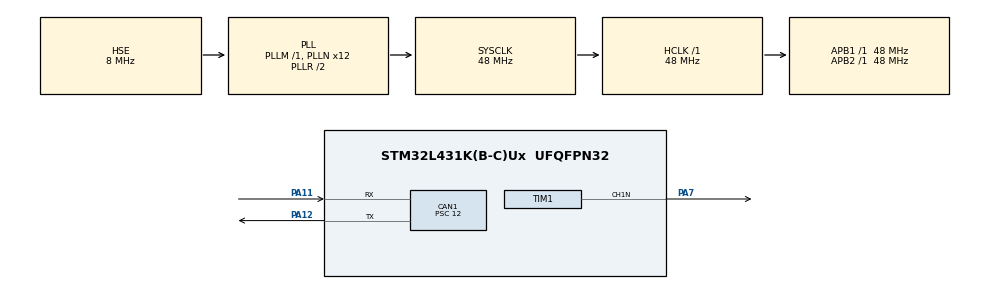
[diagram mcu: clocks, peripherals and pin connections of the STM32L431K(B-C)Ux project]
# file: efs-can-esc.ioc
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CAN1.BS1=CAN_BS1_2TQ
CAN1.CalculateBaudRate=1000000
CAN1.CalculateTimeBit=1000
CAN1.CalculateTimeQuantum=250.0
CAN1.Prescaler=12
Dma.Request0=TIM1_CH1
Dma.TIM1_CH1.0.Direction=DMA_MEMORY_TO_PERIPH
Dma.TIM1_CH1.0.Instance=DMA1_Channel2
Dma.TIM1_CH1.0.MemDataAlignment=DMA_MDATAALIGN_WORD
Dma.TIM1_CH1.0.MemInc=DMA_MINC_ENABLE
Dma.TIM1_CH1.0.Mode=DMA_CIRCULAR
Dma.TIM1_CH1.0.PeriphDataAlignment=DMA_PDATAALIGN_WORD
Dma.TIM1_CH1.0.PeriphInc=DMA_PINC_DISABLE
Dma.TIM1_CH1.0.Priority=DMA_PRIORITY_LOW
Mcu.Family=STM32L4
Mcu.Name=STM32L431K(B-C)Ux
Mcu.Package=UFQFPN32
NVIC.CAN1_RX0_IRQn=true\:0\:0\:false\:false\:true\:true\:true\:true
NVIC.DMA1_Channel2_IRQn=true\:0\:0\:false\:false\:true\:false\:true\:true
NVIC.PriorityGroup=NVIC_PRIORITYGROUP_4
PA0.Mode=HSE-External-Clock-Source-for-LittleOrca
PA0.Signal=RCC_CK_IN
PA11.GPIO_PuPd=GPIO_PULLUP
PA11.Mode=CAN_Activate
PA11.Signal=CAN1_RX
PA12.Mode=CAN_Activate
PA12.Signal=CAN1_TX
PA13\ (JTMS-SWDIO).Mode=Trace_Asynchronous_SW
PA13\ (JTMS-SWDIO).Signal=SYS_JTMS-SWDIO
PA14\ (JTCK-SWCLK).Mode=Trace_Asynchronous_SW
PA14\ (JTCK-SWCLK).Signal=SYS_JTCK-SWCLK
PA7.Mode=PWM Generation1 CH1N
PA7.Signal=TIM1_CH1N
PB3\ (JTDO-TRACESWO).Mode=Trace_Asynchronous_SW
PB3\ (JTDO-TRACESWO).Signal=SYS_JTDO-SWO
ProjectManager.HeapSize=0x200
ProjectManager.StackSize=0x400
ProjectManager.TargetToolchain=STM32CubeIDE
RCC.ADCFreq_Value=32000000
RCC.AHBFreq_Value=48000000
RCC.APB1Freq_Value=48000000
RCC.APB1TimFreq_Value=48000000
RCC.APB2Freq_Value=48000000
RCC.APB2TimFreq_Value=48000000
RCC.CortexFreq_Value=48000000
RCC.HCLKFreq_Value=48000000
RCC.HSE_VALUE=8000000
RCC.HSI48_VALUE=48000000
RCC.HSI_VALUE=16000000
RCC.LSE_VALUE=32768
RCC.MSI_VALUE=4000000
RCC.PLLN=12
RCC.PLLSourceVirtual=RCC_PLLSOURCE_HSE
RCC.SYSCLKFreq_VALUE=48000000
RCC.SYSCLKSource=RCC_SYSCLKSOURCE_PLLCLK
RCC.VCOOutputFreq_Value=96000000
TIM1.Channel-PWM\ Generation1\ CH1N=TIM_CHANNEL_1
TIM1.OCMode_PWM-PWM\ Generation1\ CH1N=TIM_OCMODE_PWM1
TIM1.OCNIdleState_1=TIM_OCNIDLESTATE_SET
TIM1.Period=320
VP_TIM1_VS_ClockSourceINT.Mode=Internal
board=custom

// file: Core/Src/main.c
/* USER CODE BEGIN Header */
/**
  ******************************************************************************
  * @file           : main.c
  * @brief          : Main program body
  ******************************************************************************
  * @attention
  *
  * Copyright (c) 2024 STMicroelectronics.
  * All rights reserved.
  *
  * This software is licensed under terms that can be found in the LICENSE file
  * in the root directory of this software component.
  * If no LICENSE file comes with this software, it is provided AS-IS.
  *
  ******************************************************************************
  */
/* USER CODE END Header */
#include "main.h"

/* USER CODE BEGIN Includes */
#include <canard.h>
#include <canard_stm32_driver.h>
#include <dronecan_msgs.h>
#include <Dshot.h>
#include <node_settings.h>
#include <stdio.h>
#include <string.h>
/* USER CODE END Includes */

CAN_HandleTypeDef hcan1;

TIM_HandleTypeDef htim1;
DMA_HandleTypeDef hdma_tim1_ch1;

/* USER CODE BEGIN PV */
CanardInstance canard;
DShotConfig_t dshotConfig = {};
float global_throttle = 0.0;
uint8_t memory_pool[1024];
static struct uavcan_protocol_NodeStatus node_status;
/* USER CODE END PV */

void SystemClock_Config(void);
static void MX_GPIO_Init(void);
static void MX_DMA_Init(void);
static void MX_TIM1_Init(void);
static void MX_CAN1_Init(void);

/* USER CODE BEGIN 0 */

// NOTE: All canard handlers and senders are based on this reference: https://dronecan.github.io/Specification/7._List_of_standard_data_types/
// Alternatively, you can look at the corresponding generated header file in the dsdlc_generated folder

// Canard Handlers ( Many have code copied from libcanard esc_node example: https://github.com/dronecan/libcanard/blob/master/examples/ESCNode/esc_node.c )

void handle_NodeStatus(CanardInstance *ins, CanardRxTransfer *transfer) {
	struct uavcan_protocol_NodeStatus nodeStatus;

	if (uavcan_protocol_NodeStatus_decode(transfer, &nodeStatus)) {
		return;
	}

	printf("Node health: %ud Node Mode: %ud\n", nodeStatus.health, nodeStatus.mode);

	printf("Node Health ");

	switch (nodeStatus.health) {
	case UAVCAN_PROTOCOL_NODESTATUS_HEALTH_OK:
		printf("OK\n");
		break;
	case UAVCAN_PROTOCOL_NODESTATUS_HEALTH_WARNING:
		printf("WARNING\n");
		break;
	case UAVCAN_PROTOCOL_NODESTATUS_HEALTH_ERROR:
		printf("ERROR\n");
		break;
	case UAVCAN_PROTOCOL_NODESTATUS_HEALTH_CRITICAL:
		printf("CRITICAL\n");
		break;
	default:
		printf("UNKNOWN?\n");
		break;
	}

	printf("Node Mode ");

	switch(nodeStatus.mode) {
	case UAVCAN_PROTOCOL_NODESTATUS_MODE_OPERATIONAL:
		printf("OPERATIONAL\n");
		break;
	case UAVCAN_PROTOCOL_NODESTATUS_MODE_INITIALIZATION:
		printf("INITIALIZATION\n");
		break;
	case UAVCAN_PROTOCOL_NODESTATUS_MODE_MAINTENANCE:
		printf("MAINTENANCE\n");
		break;
	case UAVCAN_PROTOCOL_NODESTATUS_MODE_SOFTWARE_UPDATE:
		printf("SOFTWARE UPDATE\n");
		break;
	case UAVCAN_PROTOCOL_NODESTATUS_MODE_OFFLINE:
		printf("OFFLINE\n");
		break;
	default:
		printf("UNKNOWN?\n");
		break;
	}
}

void handle_NotifyState(CanardInstance *ins, CanardRxTransfer *transfer) {
	struct ardupilot_indication_NotifyState notifyState;

	if (ardupilot_indication_NotifyState_decode(transfer, &notifyState)) {
		return;
	}

	uint32_t nl = notifyState.vehicle_state & 0xFFFFFFFF;  // ignoring the last 32 bits for printing since the highest vehicle_state value right now is 23 even though they're allowed to be up to 64bit unsigned integer

	printf("Vehicle State: %lu ", nl);

	if (notifyState.aux_data.len > 0) {
		printf("Aux Data: 0x");

		for (int i = 0; i < notifyState.aux_data.len; i++) {
			printf("%02x", notifyState.aux_data.data[i]);
		}
	}

	printf("\n");

}

/*
  get a 16 byte unique ID for this node, this should be based on the CPU unique ID or other unique ID
 */
void getUniqueID(uint8_t id[16]) {
    uint32_t HALUniqueIDs[3];
    // Make Unique ID out of the 96-bit STM32 UID and fill the rest with 0s
    memset(id, 0, 16);
    HALUniqueIDs[0] = HAL_GetUIDw0();
    HALUniqueIDs[1] = HAL_GetUIDw1();
    HALUniqueIDs[2] = HAL_GetUIDw2();
    memcpy(id, HALUniqueIDs, 12);
}

/*
  handle a GetNodeInfo request
*/
// TODO: All the data in here is temporary for testing. If actually need to send valid data, edit accordingly.
void handle_GetNodeInfo(CanardInstance *ins, CanardRxTransfer *transfer) {
	printf("GetNodeInfo request from %d\n", transfer->source_node_id);

	uint8_t buffer[UAVCAN_PROTOCOL_GETNODEINFO_RESPONSE_MAX_SIZE];
	struct uavcan_protocol_GetNodeInfoResponse pkt;

	memset(&pkt, 0, sizeof(pkt));

	node_status.uptime_sec = HAL_GetTick() / 1000ULL;
	pkt.status = node_status;

	// fill in your major and minor firmware version
	pkt.software_version.major = 1;
	pkt.software_version.minor = 0;
	pkt.software_version.optional_field_flags = 0;
	pkt.software_version.vcs_commit = 0; // should put git hash in here

	// should fill in hardware version
	pkt.hardware_version.major = 1;
	pkt.hardware_version.minor = 0;

	// just setting all 16 bytes to 1 for testing
	getUniqueID(pkt.hardware_version.unique_id);

	strncpy((char*)pkt.name.data, "ESCNode", sizeof(pkt.name.data));
	pkt.name.len = strnlen((char*)pkt.name.data, sizeof(pkt.name.data));

	uint16_t total_size = uavcan_protocol_GetNodeInfoResponse_encode(&pkt, buffer);

	canardRequestOrRespond(ins,
						   transfer->source_node_id,
						   UAVCAN_PROTOCOL_GETNODEINFO_SIGNATURE,
						   UAVCAN_PROTOCOL_GETNODEINFO_ID,
						   &transfer->transfer_id,
						   transfer->priority,
						   CanardResponse,
						   &buffer[0],
						   total_size);
}

/*
  handle a ESC RawCommand request
*/
void handle_RawCommand(CanardInstance *ins, CanardRxTransfer *transfer)
{
  struct uavcan_equipment_esc_RawCommand rawCommand;
  if (uavcan_equipment_esc_RawCommand_decode(transfer, &rawCommand)) {
    return;
  }

  // see if it is for us
  if (rawCommand.cmd.len <= ESC_INDEX) {
    return;
  }

  // convert throttle to -100 to 100 range and update the global value
  float throttle = rawCommand.cmd.data[ESC_INDEX]/8192.0*100;
  global_throttle = throttle;

}

// CAN ISR
// Run HAL_CAN_ActivateNotification(&hcan1, CAN_IT_RX_FIFO0_MSG_PENDING) once to set up the ISR
void HAL_CAN_RxFifo0MsgPendingCallback(CAN_HandleTypeDef *hcan) {
	// Receiving
	CanardCANFrame rx_frame;

	const uint64_t timestamp = HAL_GetTick() * 1000ULL;
	const int16_t rx_res = canardSTM32Recieve(hcan, CAN_RX_FIFO0, &rx_frame);

	if (rx_res < 0) {
		printf("Receive error %d\n", rx_res);
	}
	else if (rx_res > 0)        // Success - process the frame
	{
		canardHandleRxFrame(&canard, &rx_frame, timestamp);
	}
}

bool shouldAcceptTransfer(const CanardInstance *ins,
                                 uint64_t *out_data_type_signature,
                                 uint16_t data_type_id,
                                 CanardTransferType transfer_type,
                                 uint8_t source_node_id)
{
	if (transfer_type == CanardTransferTypeRequest) {
	// check if we want to handle a specific service request
		switch (data_type_id) {
		case UAVCAN_PROTOCOL_GETNODEINFO_ID: {
			*out_data_type_signature = UAVCAN_PROTOCOL_GETNODEINFO_REQUEST_SIGNATURE;
			return true;
		}
		}
	}
	if (transfer_type == CanardTransferTypeResponse) {
		// check if we want to handle a specific service request
		switch (data_type_id) {
		}
	}
	if (transfer_type == CanardTransferTypeBroadcast) {
		// see if we want to handle a specific broadcast packet
		switch (data_type_id) {
		case UAVCAN_EQUIPMENT_ESC_RAWCOMMAND_ID: {
			*out_data_type_signature = UAVCAN_EQUIPMENT_ESC_RAWCOMMAND_SIGNATURE;
			return true;
		}
		case UAVCAN_PROTOCOL_NODESTATUS_ID: {
			*out_data_type_signature = UAVCAN_PROTOCOL_NODESTATUS_SIGNATURE;
			return true;
		}
		case ARDUPILOT_INDICATION_NOTIFYSTATE_ID: {
			*out_data_type_signature = ARDUPILOT_INDICATION_NOTIFYSTATE_SIGNATURE;
			return true;
		}
		}
	}
	// we don't want any other messages
	return false;
}

void onTransferReceived(CanardInstance *ins, CanardRxTransfer *transfer) {
	// switch on data type ID to pass to the right handler function
//	printf("Transfer type: %du, Transfer ID: %du \n", transfer->transfer_type, transfer->data_type_id);
//	printf("0x");
//		for (int i = 0; i < transfer->payload_len; i++) {
//			printf("%02x", transfer->payload_head[i]);
//		}
//
//		printf("\n");
	if (transfer->transfer_type == CanardTransferTypeRequest) {
		// check if we want to handle a specific service request
		switch (transfer->data_type_id) {
		case UAVCAN_PROTOCOL_GETNODEINFO_ID: {
			handle_GetNodeInfo(ins, transfer);
			break;
		}
		}
	}
	if (transfer->transfer_type == CanardTransferTypeResponse) {
		switch (transfer->data_type_id) {
		}
	}
	if (transfer->transfer_type == CanardTransferTypeBroadcast) {
		// check if we want to handle a specific broadcast message
		switch (transfer->data_type_id) {
		case UAVCAN_EQUIPMENT_ESC_RAWCOMMAND_ID: {
			handle_RawCommand(ins, transfer);
			break;
		}
		case UAVCAN_PROTOCOL_NODESTATUS_ID: {
			handle_NodeStatus(ins, transfer);
			break;
		}
		case ARDUPILOT_INDICATION_NOTIFYSTATE_ID: {
			handle_NotifyState(ins, transfer);
			break;
		}
		}
	}
}

// CAN Filter setup, modify this to your needs
// Run this once before calling HAL_CAN_Start()
void setupCANFilter(CAN_HandleTypeDef *hcan) {
  CAN_FilterTypeDef filter;
  filter.FilterBank = 0;
	filter.FilterMode = CAN_FILTERMODE_IDMASK;
	filter.FilterFIFOAssignment = CAN_RX_FIFO0;
	filter.FilterIdHigh = 0;
	filter.FilterIdLow = 0;
	filter.FilterMaskIdHigh = 0;
	filter.FilterMaskIdLow = 0;
	filter.FilterScale = CAN_FILTERSCALE_32BIT;
	filter.FilterActivation = ENABLE;
	filter.SlaveStartFilterBank = 14;

	HAL_CAN_ConfigFilter(hcan, &filter);
}

/* USER CODE END 0 */

int main(void)
{

  /* MCU Configuration--------------------------------------------------------*/

  /* Reset of all peripherals, Initializes the Flash interface and the Systick. */
  HAL_Init();

  /* Configure the system clock */
  SystemClock_Config();

  /* Initialize all configured peripherals */
  MX_GPIO_Init();
  MX_DMA_Init();
  MX_TIM1_Init();
  MX_CAN1_Init();
  /* USER CODE BEGIN 2 */

  /* Initialize DShot */
  uint32_t buffer[DSHOT_DMA_BUFFER_LEN] = {0};
  dshotConfig.timer = &htim1;
  dshotConfig.timerChannel = TIM_CHANNEL_1;
  dshotConfig.timDMAHandleIndex = TIM_DMA_ID_CC1;
  dshotConfig.dmaBuffer = buffer;
  dshotInit(dshotConfig);

  /* Initialize CAN ISR, CAN Filter, and CAN module  */
  HAL_CAN_ActivateNotification(&hcan1, CAN_IT_RX_FIFO0_MSG_PENDING);
  setupCANFilter(&hcan1);
  HAL_CAN_Start(&hcan1);

  /*
   Initializing the Libcanard instance.
   */
  canardInit(&canard,
			 memory_pool,
			 sizeof(memory_pool),
			 onTransferReceived,
			 shouldAcceptTransfer,
			 NULL);

  // Set a different NODE_ID for each device on the CAN bus by configuring node_settings
  if (NODE_ID > 0) {
	  canardSetLocalNodeID(&canard, NODE_ID);
  } else {
	  printf("Node ID is 0, this node is anonymous and can't transmit most messaged. Please update this in node_settings.h\n");
  }

  /* USER CODE END 2 */

  /* Infinite loop */
  /* USER CODE BEGIN WHILE */
  while (1)
  {
    // global_throttle is updated by handle_RawCommand when ESC CAN message is received.
    dshotWrite(dshotConfig, global_throttle, 0);
    HAL_Delay(1000);

    /* USER CODE END WHILE */
  }
}

void SystemClock_Config(void)
{
  RCC_OscInitTypeDef RCC_OscInitStruct = {0};
  RCC_ClkInitTypeDef RCC_ClkInitStruct = {0};

  /** Configure the main internal regulator output voltage
  */
  if (HAL_PWREx_ControlVoltageScaling(PWR_REGULATOR_VOLTAGE_SCALE1) != HAL_OK)
  {
    Error_Handler();
  }

  /** Initializes the RCC Oscillators according to the specified parameters
  * in the RCC_OscInitTypeDef structure.
  */
  RCC_OscInitStruct.OscillatorType = RCC_OSCILLATORTYPE_HSE;
  RCC_OscInitStruct.HSEState = RCC_HSE_BYPASS;
  RCC_OscInitStruct.PLL.PLLState = RCC_PLL_ON;
  RCC_OscInitStruct.PLL.PLLSource = RCC_PLLSOURCE_HSE;
  RCC_OscInitStruct.PLL.PLLM = 1;
  RCC_OscInitStruct.PLL.PLLN = 12;
  RCC_OscInitStruct.PLL.PLLP = RCC_PLLP_DIV7;
  RCC_OscInitStruct.PLL.PLLQ = RCC_PLLQ_DIV2;
  RCC_OscInitStruct.PLL.PLLR = RCC_PLLR_DIV2;
  if (HAL_RCC_OscConfig(&RCC_OscInitStruct) != HAL_OK)
  {
    Error_Handler();
  }

  /** Initializes the CPU, AHB and APB buses clocks
  */
  RCC_ClkInitStruct.ClockType = RCC_CLOCKTYPE_HCLK|RCC_CLOCKTYPE_SYSCLK
                              |RCC_CLOCKTYPE_PCLK1|RCC_CLOCKTYPE_PCLK2;
  RCC_ClkInitStruct.SYSCLKSource = RCC_SYSCLKSOURCE_PLLCLK;
  RCC_ClkInitStruct.AHBCLKDivider = RCC_SYSCLK_DIV1;
  RCC_ClkInitStruct.APB1CLKDivider = RCC_HCLK_DIV1;
  RCC_ClkInitStruct.APB2CLKDivider = RCC_HCLK_DIV1;

  if (HAL_RCC_ClockConfig(&RCC_ClkInitStruct, FLASH_LATENCY_2) != HAL_OK)
  {
    Error_Handler();
  }
}

static void MX_CAN1_Init(void)
{

  hcan1.Instance = CAN1;
  hcan1.Init.Prescaler = 12;
  hcan1.Init.Mode = CAN_MODE_NORMAL;
  hcan1.Init.SyncJumpWidth = CAN_SJW_1TQ;
  hcan1.Init.TimeSeg1 = CAN_BS1_2TQ;
  hcan1.Init.TimeSeg2 = CAN_BS2_1TQ;
  hcan1.Init.TimeTriggeredMode = DISABLE;
  hcan1.Init.AutoBusOff = DISABLE;
  hcan1.Init.AutoWakeUp = DISABLE;
  hcan1.Init.AutoRetransmission = DISABLE;
  hcan1.Init.ReceiveFifoLocked = DISABLE;
  hcan1.Init.TransmitFifoPriority = DISABLE;
  if (HAL_CAN_Init(&hcan1) != HAL_OK)
  {
    Error_Handler();
  }

}

static void MX_TIM1_Init(void)
{

  TIM_ClockConfigTypeDef sClockSourceConfig = {0};
  TIM_MasterConfigTypeDef sMasterConfig = {0};
  TIM_OC_InitTypeDef sConfigOC = {0};
  TIM_BreakDeadTimeConfigTypeDef sBreakDeadTimeConfig = {0};

  htim1.Instance = TIM1;
  htim1.Init.Prescaler = 0;
  htim1.Init.CounterMode = TIM_COUNTERMODE_UP;
  htim1.Init.Period = 320;
  htim1.Init.ClockDivision = TIM_CLOCKDIVISION_DIV1;
  htim1.Init.RepetitionCounter = 0;
  htim1.Init.AutoReloadPreload = TIM_AUTORELOAD_PRELOAD_DISABLE;
  if (HAL_TIM_Base_Init(&htim1) != HAL_OK)
  {
    Error_Handler();
  }
  sClockSourceConfig.ClockSource = TIM_CLOCKSOURCE_INTERNAL;
  if (HAL_TIM_ConfigClockSource(&htim1, &sClockSourceConfig) != HAL_OK)
  {
    Error_Handler();
  }
  if (HAL_TIM_PWM_Init(&htim1) != HAL_OK)
  {
    Error_Handler();
  }
  sMasterConfig.MasterOutputTrigger = TIM_TRGO_RESET;
  sMasterConfig.MasterOutputTrigger2 = TIM_TRGO2_RESET;
  sMasterConfig.MasterSlaveMode = TIM_MASTERSLAVEMODE_DISABLE;
  if (HAL_TIMEx_MasterConfigSynchronization(&htim1, &sMasterConfig) != HAL_OK)
  {
    Error_Handler();
  }
  sConfigOC.OCMode = TIM_OCMODE_PWM1;
  sConfigOC.Pulse = 0;
  sConfigOC.OCPolarity = TIM_OCPOLARITY_HIGH;
  sConfigOC.OCNPolarity = TIM_OCNPOLARITY_HIGH;
  sConfigOC.OCFastMode = TIM_OCFAST_DISABLE;
  sConfigOC.OCIdleState = TIM_OCIDLESTATE_RESET;
  sConfigOC.OCNIdleState = TIM_OCNIDLESTATE_SET;
  if (HAL_TIM_PWM_ConfigChannel(&htim1, &sConfigOC, TIM_CHANNEL_1) != HAL_OK)
  {
    Error_Handler();
  }
  sBreakDeadTimeConfig.OffStateRunMode = TIM_OSSR_DISABLE;
  sBreakDeadTimeConfig.OffStateIDLEMode = TIM_OSSI_DISABLE;
  sBreakDeadTimeConfig.LockLevel = TIM_LOCKLEVEL_OFF;
  sBreakDeadTimeConfig.DeadTime = 0;
  sBreakDeadTimeConfig.BreakState = TIM_BREAK_DISABLE;
  sBreakDeadTimeConfig.BreakPolarity = TIM_BREAKPOLARITY_HIGH;
  sBreakDeadTimeConfig.BreakFilter = 0;
  sBreakDeadTimeConfig.Break2State = TIM_BREAK2_DISABLE;
  sBreakDeadTimeConfig.Break2Polarity = TIM_BREAK2POLARITY_HIGH;
  sBreakDeadTimeConfig.Break2Filter = 0;
  sBreakDeadTimeConfig.AutomaticOutput = TIM_AUTOMATICOUTPUT_DISABLE;
  if (HAL_TIMEx_ConfigBreakDeadTime(&htim1, &sBreakDeadTimeConfig) != HAL_OK)
  {
    Error_Handler();
  }
  HAL_TIM_MspPostInit(&htim1);

}

static void MX_DMA_Init(void)
{

  /* DMA controller clock enable */
  __HAL_RCC_DMA1_CLK_ENABLE();

  /* DMA interrupt init */
  /* DMA1_Channel2_IRQn interrupt configuration */
  HAL_NVIC_SetPriority(DMA1_Channel2_IRQn, 0, 0);
  HAL_NVIC_EnableIRQ(DMA1_Channel2_IRQn);

}

static void MX_GPIO_Init(void)
{

  /* GPIO Ports Clock Enable */
  __HAL_RCC_GPIOA_CLK_ENABLE();
  __HAL_RCC_GPIOB_CLK_ENABLE();

}

/* USER CODE BEGIN 4 */
int __io_putchar(int ch)
{
	return ITM_SendChar(ch);
}
/* USER CODE END 4 */

void Error_Handler(void)
{
  __disable_irq();
  while (1)
  {
  }
}
